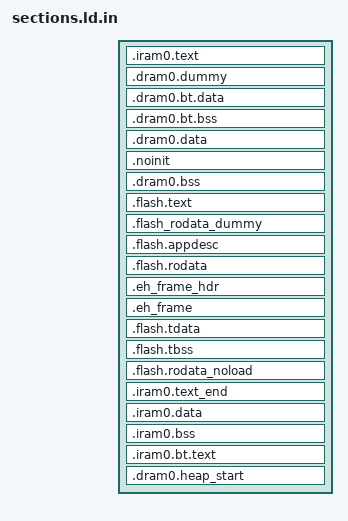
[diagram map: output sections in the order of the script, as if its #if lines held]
/*
 * SPDX-FileCopyrightText: 2021 Espressif Systems (Shanghai) CO LTD
 *
 * SPDX-License-Identifier: Apache-2.0
 */

#include "ld.common"

/* Default entry point */
ENTRY(call_start_cpu0);

SECTIONS
{
  .iram0.text :
  {
    _iram_start = ABSOLUTE(.);
    /* Vectors go to start of IRAM */
    ASSERT(ABSOLUTE(.) % 0x100 == 0, "vector address must be 256 byte aligned");
    KEEP(*(.exception_vectors_table.text));
    KEEP(*(.exception_vectors.text));

    ALIGNED_SYMBOL(4, _invalid_pc_placeholder)

    /* Code marked as running out of IRAM */
    _iram_text_start = ABSOLUTE(.);

    mapping[iram0_text]

  } > iram0_0_seg

  /**
   * This section is required to skip .iram0.text area because iram0_0_seg and
   * dram0_0_seg reflect the same address space on different buses.
   */
  .dram0.dummy (NOLOAD):
  {
    . = ORIGIN(dram0_0_seg) + _iram_end - _iram_start;
  } > dram0_0_seg

  /**
   * This section MUST be placed at the beginning of the DRAM0, which will be
   * released along with iram0_bt.text when Bluetooth is no longer in use.
   */
 .dram0.bt.data :
  {
    _data_start = ABSOLUTE(.);
    mapping[dram0_bt_data]
  } > dram0_0_seg

  .dram0.bt.bss (NOLOAD) :
  {
    ALIGNED_SYMBOL(8, _bss_bt_start)

    mapping[dram0_bt_bss]

    _bss_bt_end = ABSOLUTE(.);
  } > dram0_0_seg

  .dram0.data :
  {
    *(.gnu.linkonce.d.*)
    *(.data1)
    __global_pointer$ = . + 0x800;
    *(.sdata)
    *(.sdata.*)
    *(.gnu.linkonce.s.*)
    *(.gnu.linkonce.s2.*)
    *(.jcr)

    mapping[dram0_data]

    _data_end = ABSOLUTE(.);
  } > dram0_0_seg

  /**
   * This section holds data that should not be initialized at power up.
   * The section located in Internal SRAM memory region. The macro _NOINIT
   * can be used as attribute to place data into this section.
   * See the "esp_attr.h" file for more information.
   */
  .noinit (NOLOAD):
  {
    ALIGNED_SYMBOL(4, _noinit_start)

    *(.noinit .noinit.*)

    ALIGNED_SYMBOL(4, _noinit_end)
  } > dram0_0_seg

  /* Shared RAM */
  .dram0.bss (NOLOAD) :
  {
    ALIGNED_SYMBOL(8, _bss_start)

    /**
     * ldgen places all bss-related data to mapping[dram0_bss]
     * (See components/esp_system/app.lf).
     */
    mapping[dram0_bss]

    ALIGNED_SYMBOL(8, _bss_end)
  } > dram0_0_seg

  ASSERT(((_bss_end - ORIGIN(dram0_0_seg)) <= LENGTH(dram0_0_seg)),
         "DRAM segment data does not fit.")

  .flash.text :
  {
    _stext = .;
    /**
     * Mark the start of flash.text.
     * This can be used by the MMU driver to maintain the virtual address.
     */
    _instruction_reserved_start = ABSOLUTE(.);
    _text_start = ABSOLUTE(.);

    mapping[flash_text]

    *(.stub)
    *(.gnu.linkonce.t.*)
    *(.gnu.warning)
    *(.irom0.text) /* catch stray ICACHE_RODATA_ATTR */

    /**
     * CPU will try to prefetch up to 16 bytes of of instructions.
     * This means that any configuration (e.g. MMU, PMS) must allow
     * safe access to up to 16 bytes after the last real instruction, add
     * dummy bytes to ensure this
     */
    . += _esp_flash_mmap_prefetch_pad_size;

    _text_end = ABSOLUTE(.);
    /**
     * Mark the flash.text end.
     * This can be used for MMU driver to maintain virtual address.
     */
    _instruction_reserved_end = ABSOLUTE(.);
    _etext = .;

    /**
     * Similar to _iram_start, this symbol goes here so it is
     * resolved by addr2line in preference to the first symbol in
     * the flash.text segment.
     */
    _flash_cache_start = ABSOLUTE(0);
  } > default_code_seg

  /**
   * Dummy section represents the .flash.text section but in default_rodata_seg.
   * Thus, it must have its alignment and (at least) its size.
   */
  .flash_rodata_dummy (NOLOAD):
  {
    _flash_rodata_dummy_start = .;

    . = ALIGN(ALIGNOF(.flash.text)) + SIZEOF(.flash.text);

    /* Add alignment of MMU page size + 0x20 bytes for the mapping header. */
    . = ALIGN(_esp_mmu_page_size) + 0x20;
  } > default_rodata_seg

  .flash.appdesc : ALIGN(0x10)
  {
    /**
     * Mark flash.rodata start.
     * This can be used for mmu driver to maintain virtual address
     */
    _rodata_reserved_start = ABSOLUTE(.);
    _rodata_start = ABSOLUTE(.);

    /* !DO NOT PUT ANYTHING BEFORE THIS! */

    /* Should be the first.  App version info. */
    *(.rodata_desc .rodata_desc.*)
    /* Should be the second. Custom app version info. */
    *(.rodata_custom_desc .rodata_custom_desc.*)

    /**
     * Create an empty gap within this section. Thanks to this, the end of this
     * section will match .flash.rodata's begin address. Thus, both sections
     * will be merged when creating the final bin image.
     */
    . = ALIGN(ALIGNOF(.flash.rodata));
  } > default_rodata_seg
  ASSERT_SECTIONS_GAP(.flash.appdesc, .flash.rodata)

  .flash.rodata : ALIGN(0x10)
  {
    _flash_rodata_start = ABSOLUTE(.);

    mapping[flash_rodata]

    *(.irom1.text) /* catch stray ICACHE_RODATA_ATTR */
    *(.gnu.linkonce.r.*)
    *(.rodata1)
    *(.gcc_except_table .gcc_except_table.*)
    *(.gnu.linkonce.e.*)
    /**
     * C++ constructor tables.
     *
     * Excluding crtbegin.o/crtend.o since IDF doesn't use the toolchain crt.
     *
     * RISC-V gcc is configured with --enable-initfini-array so it emits
     * .init_array section instead. But the init_priority sections will be
     * sorted for iteration in ascending order during startup.
     * The rest of the init_array sections is sorted for iteration in descending
     * order during startup, however. Hence a different section is generated for
     * the init_priority functions which is iterated in ascending order during
     * startup. The corresponding code can be found in startup.c.
     */
    ALIGNED_SYMBOL(4, __init_priority_array_start)
    KEEP (*(EXCLUDE_FILE (*crtend.* *crtbegin.*) .init_array.*))
    __init_priority_array_end = ABSOLUTE(.);

    ALIGNED_SYMBOL(4, __init_array_start)
    KEEP (*(EXCLUDE_FILE (*crtend.* *crtbegin.*) .init_array))
    __init_array_end = ABSOLUTE(.);

    /* Addresses of memory regions reserved via SOC_RESERVE_MEMORY_REGION() */
    ALIGNED_SYMBOL(4, soc_reserved_memory_region_start)
    KEEP (*(.reserved_memory_address))
    soc_reserved_memory_region_end = ABSOLUTE(.);

    /* System init functions registered via ESP_SYSTEM_INIT_FN */
    ALIGNED_SYMBOL(4, _esp_system_init_fn_array_start)
    KEEP (*(SORT_BY_INIT_PRIORITY(.esp_system_init_fn.*)))
    _esp_system_init_fn_array_end = ABSOLUTE(.);

    _rodata_end = ABSOLUTE(.);
    . = ALIGN(ALIGNOF(.eh_frame_hdr));
  } > default_rodata_seg
  ASSERT_SECTIONS_GAP(.flash.rodata, .eh_frame_hdr)

  .eh_frame_hdr :
  {
#if CONFIG_COMPILER_CXX_EXCEPTIONS || CONFIG_ESP_SYSTEM_USE_EH_FRAME
    ALIGNED_SYMBOL(4, __eh_frame_hdr)

    KEEP (*(.eh_frame_hdr))

    __eh_frame_hdr_end = ABSOLUTE(.);
#endif // CONFIG_COMPILER_CXX_EXCEPTIONS || CONFIG_ESP_SYSTEM_USE_EH_FRAME

    . = ALIGN(ALIGNOF(.eh_frame));
  } > default_rodata_seg
  ASSERT_SECTIONS_GAP(.eh_frame_hdr, .eh_frame)

  .eh_frame :
  {
#if CONFIG_COMPILER_CXX_EXCEPTIONS || CONFIG_ESP_SYSTEM_USE_EH_FRAME
    ALIGNED_SYMBOL(4, __eh_frame)

    KEEP (*(.eh_frame))
    /**
     * As we are not linking with crtend.o, which includes the CIE terminator
     * (see __FRAME_END__ in libgcc sources), it is manually provided here.
     */
    LONG(0);

    __eh_frame_end = ABSOLUTE(.);
#endif // CONFIG_COMPILER_CXX_EXCEPTIONS || CONFIG_ESP_SYSTEM_USE_EH_FRAME

    . = ALIGN(ALIGNOF(.flash.tdata));
  } > default_rodata_seg
  ASSERT_SECTIONS_GAP(.eh_frame, .flash.tdata)

  .flash.tdata :
  {
    _thread_local_data_start = ABSOLUTE(.);

    *(.tdata .tdata.* .gnu.linkonce.td.*)

    . = ALIGN(ALIGNOF(.flash.tbss));
    _thread_local_data_end = ABSOLUTE(.);
  } > default_rodata_seg
  ASSERT_SECTIONS_GAP(.flash.tdata, .flash.tbss)

  .flash.tbss (NOLOAD) :
  {
    _thread_local_bss_start = ABSOLUTE(.);

    *(.tbss .tbss.* .gnu.linkonce.tb.*)
    *(.tcommon .tcommon.*)

    _thread_local_bss_end = ABSOLUTE(.);
  } > default_rodata_seg

  /**
   * This section contains all the rodata that is not used
   * at runtime, helping to avoid an increase in binary size.
   */
  .flash.rodata_noload (NOLOAD) :
  {
    /**
     * This symbol marks the end of flash.rodata. It can be utilized by the MMU
     * driver to maintain the virtual address.
     * NOLOAD rodata may not be included in this section.
     */
    _rodata_reserved_end = ADDR(.flash.tbss);

    mapping[rodata_noload]
  } > default_rodata_seg

  /* Marks the end of IRAM code segment */
  .iram0.text_end (NOLOAD) :
  {
    ALIGNED_SYMBOL(4, _iram_text_end)
  } > iram0_0_seg

  .iram0.data :
  {
    ALIGNED_SYMBOL(16, _iram_data_start)

    mapping[iram0_data]

    _iram_data_end = ABSOLUTE(.);
  } > iram0_0_seg

  .iram0.bss (NOLOAD) :
  {
    ALIGNED_SYMBOL(16, _iram_bss_start)

    mapping[iram0_bss]

    _iram_bss_end = ABSOLUTE(.);
  } > iram0_0_seg

  /**
   * This section needs to be placed at the end of the IRAM0, which will be
   * released along with dram0_bt_data and dram0_bt_bss when Bluetooth is no
   * longer in use.
   */
  .iram0.bt.text :
  {
    ALIGNED_SYMBOL(16, _iram_bt_text_start)

    mapping[iram0_bt_text]

    ALIGNED_SYMBOL(16, _iram_end)
  } > iram0_0_seg

  /* Marks the end of data, bss and possibly rodata */
  .dram0.heap_start (NOLOAD) :
  {
    ALIGNED_SYMBOL(16, _heap_start)
  } > dram0_0_seg

#include "elf_misc.ld.in"
}

ASSERT(((_iram_end - ORIGIN(iram0_0_seg)) <= LENGTH(iram0_0_seg)),
          "IRAM0 segment data does not fit.")

ASSERT(((_heap_start - ORIGIN(dram0_0_seg)) <= LENGTH(dram0_0_seg)),
          "DRAM segment data does not fit.")
